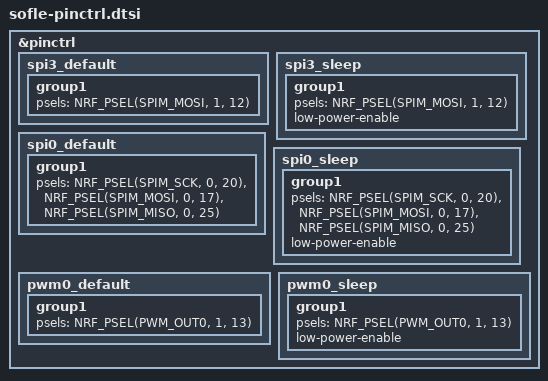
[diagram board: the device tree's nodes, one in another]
&pinctrl {
    spi3_default: spi3_default {
        group1 {
            psels = <NRF_PSEL(SPIM_MOSI, 1, 12)>; // WS2812_VEXT_DATA
        };
    };

    spi3_sleep: spi3_sleep {
        group1 {
            psels = <NRF_PSEL(SPIM_MOSI, 1, 12)>;
            low-power-enable;
        };
    };

    spi0_default: spi0_default {
        group1 {
            psels = <NRF_PSEL(SPIM_SCK, 0, 20)>,
                <NRF_PSEL(SPIM_MOSI, 0, 17)>,
                <NRF_PSEL(SPIM_MISO, 0, 25)>;
        };
    };

    spi0_sleep: spi0_sleep {
        group1 {
            psels = <NRF_PSEL(SPIM_SCK, 0, 20)>,
                <NRF_PSEL(SPIM_MOSI, 0, 17)>,
                <NRF_PSEL(SPIM_MISO, 0, 25)>;
            low-power-enable;
        };
    };

    pwm0_default: pwm0_default {
        group1 {
            psels = <NRF_PSEL(PWM_OUT0, 1, 13)>;
        };
    };
    pwm0_sleep: pwm0_sleep {
        group1 {
            psels = <NRF_PSEL(PWM_OUT0, 1, 13)>;
            low-power-enable;
        };
    };
};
